# DECODER0_PVDEC_CORE register map
Vendor: Texas Instruments
Peripheral module from a debugger description file (folder J7ES).
Registers are 32-bit, read-write, reset 0x0 unless marked. A register's access mark holds for its fields unless they carry their own. Offsets are as the file gives them; lines under a group give offsets from that group; [hi:lo] are bit positions; {n}, {i} and the like mark numbered series; 'fields as' and 'values as' point back to an identical list; <NAME> marks a mode.

## DECODER0_PVDEC_CORE
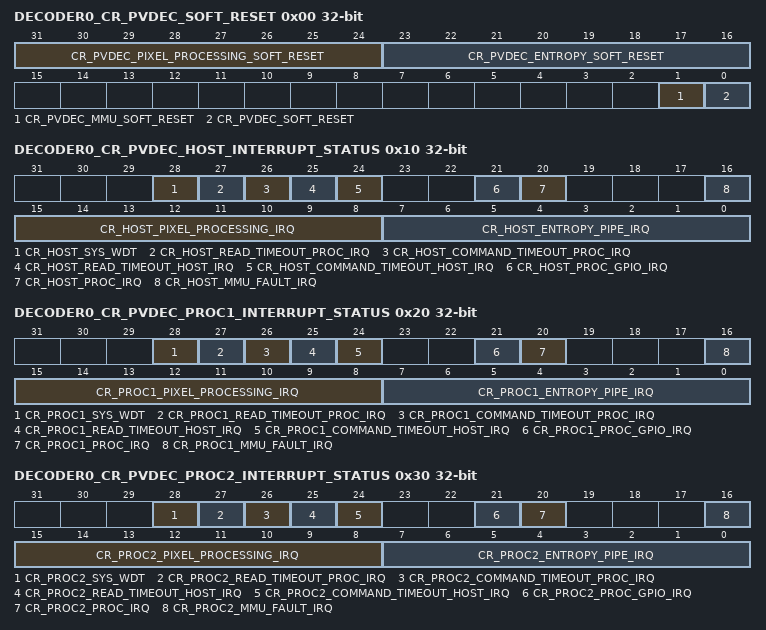
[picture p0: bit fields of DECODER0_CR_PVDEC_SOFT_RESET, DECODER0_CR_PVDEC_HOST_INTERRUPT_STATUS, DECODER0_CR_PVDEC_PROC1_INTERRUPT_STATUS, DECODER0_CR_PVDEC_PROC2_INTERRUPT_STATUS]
0x00 DECODER0_CR_PVDEC_SOFT_RESET
  [31:24] CR_PVDEC_PIXEL_PROCESSING_SOFT_RESET — For each instance of the back-end pixel processing pipe, writing '1' to this bit resets the corresponding pixel processing pipe [where bit 0 resets 'pipe 1', etc.].
  [23:16] CR_PVDEC_ENTROPY_SOFT_RESET — For each instance of the front-end entropy pipe, writing '1' to this bit resets the corresponding front-end entropy pipe [where bit 0 resets 'pipe 1', etc.].
  [1] CR_PVDEC_MMU_SOFT_RESET — Allows the MMU to be reset.
  [0] CR_PVDEC_SOFT_RESET — Allows the core to be reset.
0x10 DECODER0_CR_PVDEC_HOST_INTERRUPT_STATUS
  [28] CR_HOST_SYS_WDT — Timeout condition encountered by system Watch Dog Timer [Pulse generated at event, held by edge detection logic]
  [27] CR_HOST_READ_TIMEOUT_PROC_IRQ — Embedded processor interface timeout of read [command accepted but no data returned] [Pulse generated at event, held by edge detection logic]
  [26] CR_HOST_COMMAND_TIMEOUT_PROC_IRQ — Embedded processor interface timeout of command phase [Pulse generated at event, held by edge detection logic]
  [25] CR_HOST_READ_TIMEOUT_HOST_IRQ — Host interface timeout of read [command accepted but no data returned] [Pulse generated at event, held by edge detection logic]
  [24] CR_HOST_COMMAND_TIMEOUT_HOST_IRQ — Host interface timeout of command phase [Pulse generated at event, held by edge detection logic]
  [21] CR_HOST_PROC_GPIO_IRQ — General purpose interrupt from the embedded processor [Level from register in the embedded processor]
  [20] CR_HOST_PROC_IRQ — Serious interrupt from the embedded processor.
  [16] CR_HOST_MMU_FAULT_IRQ — MMU page fault interrupt, read the
  [15:8] CR_HOST_PIXEL_PROCESSING_IRQ — Pixel processing pipe interrupt, where bit 0 corresponds to 'pixel processing pipe 1', etc.
  [7:0] CR_HOST_ENTROPY_PIPE_IRQ — Entropy pipe interrupt, where bit 0 corresponds to 'entropy pipe 1', etc.
0x14 DECODER0_CR_PVDEC_INTERRUPT_CLEAR
  [31:16] CR_IRQ_CLEAR — The value read from the top half of PVDEC interrupt status registers is based on 'input source' ORed with 'rising edge detection' logic.
0x18 DECODER0_CR_PVDEC_HOST_INTERRUPT_ENABLE
  [31:16] CR_HOST_IRQ_ENABLE — Enables interrupts to the host.
0x20 DECODER0_CR_PVDEC_PROC1_INTERRUPT_STATUS
  [28] CR_PROC1_SYS_WDT — Timeout condition encountered by system Watch Dog Timer [Pulse generated at event, held by edge detection logic]
  [27] CR_PROC1_READ_TIMEOUT_PROC_IRQ — Embedded processor interface timeout of read [command accepted but no data returned] [Pulse generated at event, held by edge detection logic]
  [26] CR_PROC1_COMMAND_TIMEOUT_PROC_IRQ — Embedded processor interface timeout of command phase [Pulse generated at event, held by edge detection logic]
  [25] CR_PROC1_READ_TIMEOUT_HOST_IRQ — Host interface timeout of read [command accepted but no data returned] [Pulse generated at event, held by edge detection logic]
  [24] CR_PROC1_COMMAND_TIMEOUT_HOST_IRQ — Host interface timeout of command phase [Pulse generated at event, held by edge detection logic]
  [21] CR_PROC1_PROC_GPIO_IRQ — General purpose interrupt from the embedded processor [Level from register in the embedded processor]
  [20] CR_PROC1_PROC_IRQ — Serious interrupt from the embedded processor.
  [16] CR_PROC1_MMU_FAULT_IRQ — MMU page fault interrupt, read the
  [15:8] CR_PROC1_PIXEL_PROCESSING_IRQ — Pixel processing pipe interrupt, where bit 0 corresponds to 'pixel processing pipe 1', etc.
  [7:0] CR_PROC1_ENTROPY_PIPE_IRQ — Entropy pipe interrupt, where bit 0 corresponds to 'entropy pipe 1', etc.
0x28 DECODER0_CR_PVDEC_PROC1_INTERRUPT_ENABLE
  [31:16] CR_PROC1_IRQ_ENABLE — Enables interrupts to the embedded processor triggerA.
0x30 DECODER0_CR_PVDEC_PROC2_INTERRUPT_STATUS
  [28] CR_PROC2_SYS_WDT — Timeout condition encountered by system Watch Dog Timer [Pulse generated at event, held by edge detection logic]
  [27] CR_PROC2_READ_TIMEOUT_PROC_IRQ — Embedded processor interface timeout of read [command accepted but no data returned] [Pulse generated at event, held by edge detection logic]
  [26] CR_PROC2_COMMAND_TIMEOUT_PROC_IRQ — Embedded processor interface timeout of command phase [Pulse generated at event, held by edge detection logic]
  [25] CR_PROC2_READ_TIMEOUT_HOST_IRQ — Host interface timeout of read [command accepted but no data returned] [Pulse generated at event, held by edge detection logic]
  [24] CR_PROC2_COMMAND_TIMEOUT_HOST_IRQ — Host interface timeout of command phase [Pulse generated at event, held by edge detection logic]
  [21] CR_PROC2_PROC_GPIO_IRQ — General purpose interrupt from the embedded processor [Level from register in the embedded processor]
  [20] CR_PROC2_PROC_IRQ — Serious interrupt from the embedded processor.
  [16] CR_PROC2_MMU_FAULT_IRQ — MMU page fault interrupt, read the
  [15:8] CR_PROC2_PIXEL_PROCESSING_IRQ — Pixel processing pipe interrupt, where bit 0 corresponds to 'pixel processing pipe 1', etc.
  [7:0] CR_PROC2_ENTROPY_PIPE_IRQ — Entropy core interrupt, where bit 0 corresponds to 'entropy core 1', etc.
0x38 DECODER0_CR_PVDEC_PROC2_INTERRUPT_ENABLE
  [31:16] CR_PROC2_IRQ_ENABLE — Enables interrupts to the embedded processor triggerB.
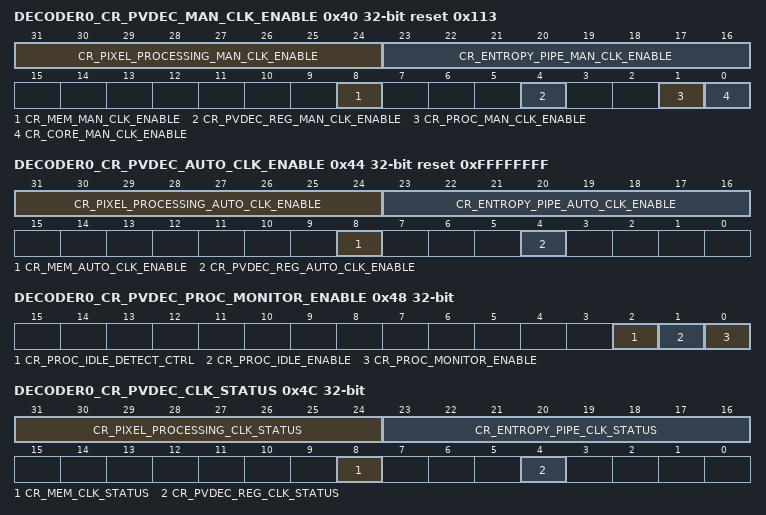
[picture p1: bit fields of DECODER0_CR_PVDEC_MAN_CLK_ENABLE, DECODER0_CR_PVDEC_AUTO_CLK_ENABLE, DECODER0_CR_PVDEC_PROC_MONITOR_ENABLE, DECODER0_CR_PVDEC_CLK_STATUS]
0x40 DECODER0_CR_PVDEC_MAN_CLK_ENABLE reset 0x113
  [31:24] CR_PIXEL_PROCESSING_MAN_CLK_ENABLE — Controls the clock for each instance of the pixel processing pipe [if this bit is set, clock is active and AUTO_CLOCK_ENABLE is ignored].
  [23:16] CR_ENTROPY_PIPE_MAN_CLK_ENABLE — Controls the clock for each instance of the entropy pipe [if this bit is set, clock is active and AUTO_CLOCK_ENABLE is ignored]
  [8] CR_MEM_MAN_CLK_ENABLE — Controls the clock for the PVDEC MMU module [If this bit is set, clock is active and AUTO_CLOCK_ENABLE is ignored]
  [4] CR_PVDEC_REG_MAN_CLK_ENABLE — Controls the clock for the PVDEC core registers [If this bit is set, clock is active and AUTO_CLOCK_ENABLE is ignored]
  [1] CR_PROC_MAN_CLK_ENABLE — Controls the clock for the embedded processor
  [0] CR_CORE_MAN_CLK_ENABLE — Controls the clock for the PVDEC core N.B.
0x44 DECODER0_CR_PVDEC_AUTO_CLK_ENABLE reset 0xFFFFFFFF
  [31:24] CR_PIXEL_PROCESSING_AUTO_CLK_ENABLE — Controls automatic clock gating for each instance of the pixel processing pipe [if MAN_CLK_ENABLE is clear and AUTO_CLOCK_ENABLE is set, clock will stop if pixel processing pipe is idle].
  [23:16] CR_ENTROPY_PIPE_AUTO_CLK_ENABLE — Controls automatic clock gating for each instance of the entropy pipe [if MAN_CLK_ENABLE is clear and AUTO_CLOCK_ENABLE is set, clock will stop if entropy pipe is idle]
  [8] CR_MEM_AUTO_CLK_ENABLE — Controls the clock for the PVDEC MMU module [if MAN_CLK_ENABLE is clear and AUTO_CLOCK_ENABLE is set, clock will stop if MMU is idle]
  [4] CR_PVDEC_REG_AUTO_CLK_ENABLE — Controls the clock for the PVDEC core registers [if MAN_CLK_ENABLE is clear and AUTO_CLOCK_ENABLE is set, clock will stop if PVDEC core register access is idle]
0x48 DECODER0_CR_PVDEC_PROC_MONITOR_ENABLE
  [2] CR_PROC_IDLE_DETECT_CTRL — Sets the method to detect the processor idle status.
  [1] CR_PROC_IDLE_ENABLE — Enables mtx idle signal for clock gating
  [0] CR_PROC_MONITOR_ENABLE — Allows proper setting of idle signals
0x4C DECODER0_CR_PVDEC_CLK_STATUS ro
  [31:24] CR_PIXEL_PROCESSING_CLK_STATUS — Indicates if the clock is enabled to each instance of the pixel processing pipe.
  [23:16] CR_ENTROPY_PIPE_CLK_STATUS — Indicates if the clock is enabled to each instance of the entropy pipe.
  [8] CR_MEM_CLK_STATUS — Indicates if the clock is enabled to MMU
  [4] CR_PVDEC_REG_CLK_STATUS — Indicates if the clock is enabled to PVDEC core registers
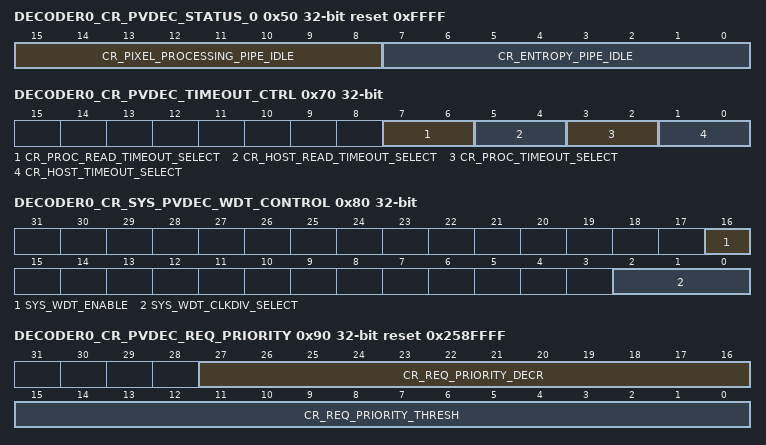
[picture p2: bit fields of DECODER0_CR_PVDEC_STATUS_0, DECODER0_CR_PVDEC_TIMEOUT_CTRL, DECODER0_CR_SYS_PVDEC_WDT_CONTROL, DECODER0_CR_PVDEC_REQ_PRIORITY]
0x50 DECODER0_CR_PVDEC_STATUS_0 ro reset 0xFFFF
  [15:8] CR_PIXEL_PROCESSING_PIPE_IDLE — Indicates the idle signal from pixel_processing_pipe [pixel_idle].
  [7:0] CR_ENTROPY_PIPE_IDLE — Indicates the idle signal from entropy_pipe [entropy_idle].
0x60 DECODER0_CR_PVDEC_HOST_PIPE_SELECT reset 0x1
  [3:0] CR_PVDEC_HOST_PIPE_SELECT — When doing read or write operations from the host to registers of the 'entropy pipe' or 'pixel processing pipe' regions in the first 64kbyte of address space, this register controls which pipeline is accessed.
0x64 DECODER0_CR_PVDEC_PROC_PIPE_SELECT reset 0x1
  [3:0] CR_PVDEC_PROC_PIPE_SELECT — When doing read or write operations from the embedded processor to registers of the 'entropy pipe' or 'pixel processing pipe' regions in the first 64kbyte of address space, this register controls which pipeline is accessed.
0x70 DECODER0_CR_PVDEC_TIMEOUT_CTRL — Controls the maximum timeout value for Host and Embedded processor accesses to the PVDEC core
  [7:6] CR_PROC_READ_TIMEOUT_SELECT — Selects the maximum number of cycles a read can remain outstanding for an embedded processor access before a timeout is flagged to indicate that PVDEC has locked up
  [5:4] CR_HOST_READ_TIMEOUT_SELECT — Selects the maximum number of cycles a read can remain outstanding for a host access before a timeout is flagged to indicate that PVDEC has locked up
  [3:2] CR_PROC_TIMEOUT_SELECT — Selects the maximum number of cycles an outstanding embedded processor access can be stalled before a timeout is flagged to indicate that PVDEC has locked up
  [1:0] CR_HOST_TIMEOUT_SELECT — Selects the maximum number of cycles an outstanding host access can be stalled before a timeout is flagged to indicate that PVDEC has locked up
0x80 DECODER0_CR_SYS_PVDEC_WDT_CONTROL
  [16] SYS_WDT_ENABLE — Watch Dog Timer enable
  [2:0] SYS_WDT_CLKDIV_SELECT — Watch Dog Timer clock select
0x84 DECODER0_CR_SYS_PVDEC_WDTIMER
  [31:0] SYS_WDT_COUNTER — Watch Dog Timer counter value.
0x90 DECODER0_CR_PVDEC_REQ_PRIORITY reset 0x258FFFF — This register controls the generation of a memory priority signal which could be used to dynamically influence the proportion of bandwidth made available to the decoder.
  [27:16] CR_REQ_PRIORITY_DECR — Programmable decrement value for performance counter in range [0,4095]
  [15:0] CR_REQ_PRIORITY_THRESH — Programmable threshold with step size 16 giving range [0,1048560]
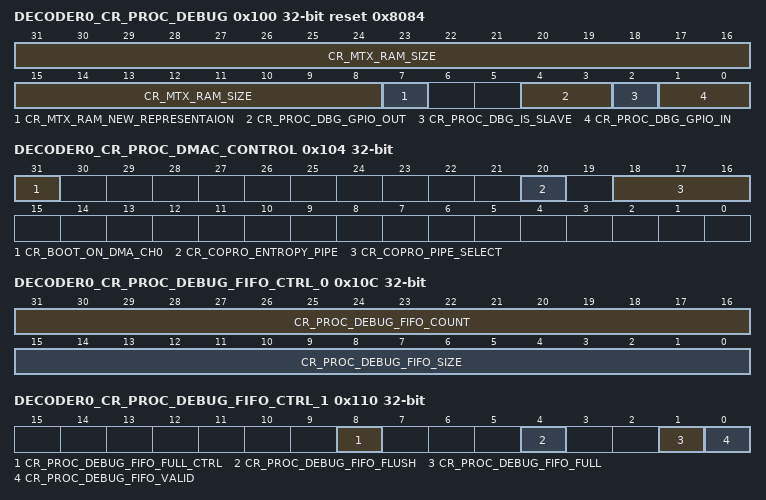
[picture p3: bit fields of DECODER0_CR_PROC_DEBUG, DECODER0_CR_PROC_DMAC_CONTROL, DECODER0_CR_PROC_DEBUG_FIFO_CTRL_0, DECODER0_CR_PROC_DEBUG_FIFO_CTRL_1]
0x100 DECODER0_CR_PROC_DEBUG reset 0x8084
  [31:8] CR_MTX_RAM_SIZE — If MTX_RAM_NEW_REPRESENTAION is 1, {
  [7] CR_MTX_RAM_NEW_REPRESENTAION — Determines whether the MTX RAM size is represented in the new way, as explained in CR_MTX_RAM_SIZE{
  [4:3] CR_PROC_DBG_GPIO_OUT — Data provided by dbg_gpio_out by the embedded processor.
  [2] CR_PROC_DBG_IS_SLAVE — Determines whether the JTAG port of the embedded processor is to be master or slave
  [1:0] CR_PROC_DBG_GPIO_IN — Data for dbg_gpio_in for the embedded processor
0x104 DECODER0_CR_PROC_DMAC_CONTROL
  [31] CR_BOOT_ON_DMA_CH0 — Enables MTX to boot upon DMA Ch0 transfer complete
  [20] CR_COPRO_ENTROPY_PIPE — If the Embedded processor co-processor port is used to access the shift register, if this field is low a Pixel Processing pipe shift register is accessed.
  [18:16] CR_COPRO_PIPE_SELECT — If the Embedded processor co-processor port is used to access the shift register, this register must specify the index of the Pixel Processing pipe or Entropy pipe which contains the shift register to be accessed.
0x108 DECODER0_CR_PROC_DEBUG_FIFO reset 0xFFFFFFFF
  [31:0] CR_PROC_DEBUG_FIFO — Embedded processor may write / read to this register location that is connected to the internal FIFO defined in the Debug FIFO Control register
0x10C DECODER0_CR_PROC_DEBUG_FIFO_CTRL_0 ro
  [31:16] CR_PROC_DEBUG_FIFO_COUNT — Number of valid DWORDS
  [15:0] CR_PROC_DEBUG_FIFO_SIZE — Depth of the Debug FIFO in DWORDS
0x110 DECODER0_CR_PROC_DEBUG_FIFO_CTRL_1
  [8] CR_PROC_DEBUG_FIFO_FULL_CTRL — Controls the write accesses when the Debug FIFO is full
  [4] CR_PROC_DEBUG_FIFO_FLUSH — Flush command for the Debug FIFO [write only]
  [1] CR_PROC_DEBUG_FIFO_FULL — Full flag of the Debug FIFO [read only]
  [0] CR_PROC_DEBUG_FIFO_VALID — Valid flag of the Debug FIFO [read only]
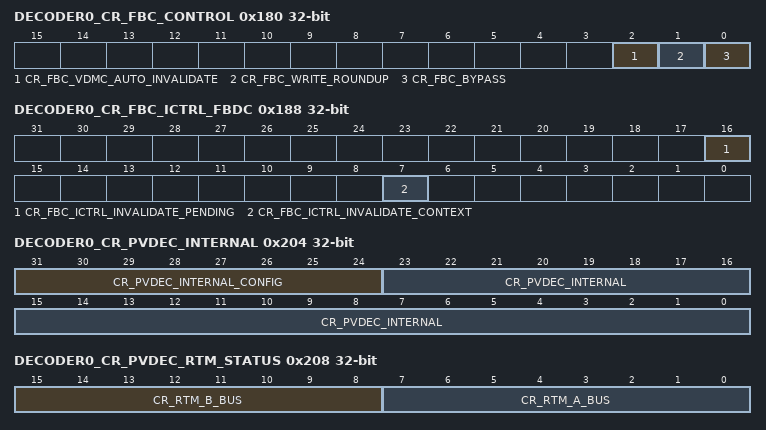
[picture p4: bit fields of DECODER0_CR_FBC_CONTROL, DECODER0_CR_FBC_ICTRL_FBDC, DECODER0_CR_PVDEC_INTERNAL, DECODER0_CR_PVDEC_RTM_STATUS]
0x180 DECODER0_CR_FBC_CONTROL
  [2] CR_FBC_VDMC_AUTO_INVALIDATE — Controls hardware invalidation of FBDC header cache
  [1] CR_FBC_WRITE_ROUNDUP — Controls write bursts for compressed data output by FBC module
  [0] CR_FBC_BYPASS — Even if commnand bus indicates frame buffer compression should be used, this field can be used to bypass the actual compression logic [but the frame store format does change to a tiled 16x4 format]
0x184 DECODER0_CR_FBC_CONTEXT
  [31:28] CR_FBC_PIPE_CONTEXT — In the case of Frame Buffer Compression being used on a multi-pipe HEVC decode, for each pixel pipe in the chain which is not the first, this field should be set to the index of the first pixel pipe in the chain [i.e.
0x188 DECODER0_CR_FBC_ICTRL_FBDC
  [16] CR_FBC_ICTRL_INVALIDATE_PENDING — Writing 1 to this bit triggers invalidation of the FBDC Header Cache, but only entries for which the corresponding context bit is set will be invalidated.
  [7] CR_FBC_ICTRL_INVALIDATE_CONTEXT — Each INVALIDATE_CONTEXT bit corresponds to requests from a specific pipe [bit 0 for pipe 1, bit 1 for pipe 2, etc].
0x204 DECODER0_CR_PVDEC_INTERNAL ro — Revision control register used internally within Imagination to record intermediate versions between release versions
  [31:24] CR_PVDEC_INTERNAL_CONFIG — Revision control register used internally within Imagination to record different hardware configurations for testing purposes
  [23:0] CR_PVDEC_INTERNAL — Revision control register used internally within Imagination to record intermediate versions between release versions
0x208 DECODER0_CR_PVDEC_RTM_STATUS ro
  [15:8] CR_RTM_B_BUS — [Read only field] Read registered version of value output on RTM bus b
  [7:0] CR_RTM_A_BUS — [Read only field] Read registered version of value output on RTM bus a
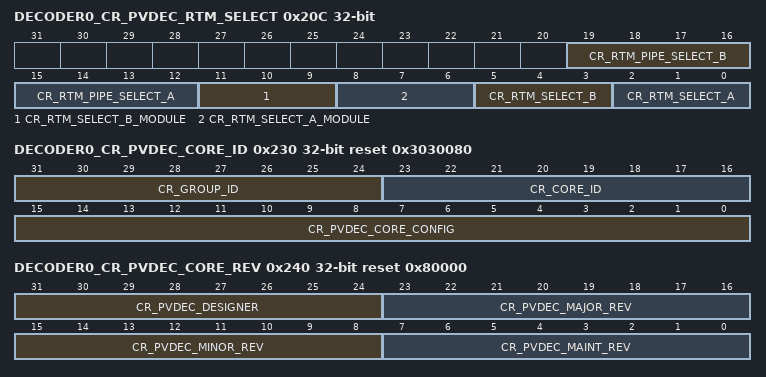
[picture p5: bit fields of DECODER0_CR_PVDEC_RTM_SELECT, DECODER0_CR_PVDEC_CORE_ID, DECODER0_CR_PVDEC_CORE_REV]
0x20C DECODER0_CR_PVDEC_RTM_SELECT
  [19:16] CR_RTM_PIPE_SELECT_B — Each pipe will generate it's own RTM bus, and this field selects the pipe to output on the common RTM bus B
  [15:12] CR_RTM_PIPE_SELECT_A — Each pipe will generate it's own RTM bus, and this field selects the pipe to output on the common RTM bus A
  [11:9] CR_RTM_SELECT_B_MODULE — Selects the module driving the upper 8 bits of the RTM bus
  [8:6] CR_RTM_SELECT_A_MODULE — Selects the module driving the lower 8 bits of the RTM bus
  [5:3] CR_RTM_SELECT_B — Selects the output for the upper 8 bits of the RTM for that module
  [2:0] CR_RTM_SELECT_A — Selects the output for the bottom 8 bits of the RTM for that module
0x230 DECODER0_CR_PVDEC_CORE_ID ro reset 0x3030080
  [31:24] CR_GROUP_ID — This identifies the core as part of an IMG IP family group.
  [23:16] CR_CORE_ID — This identifies the member of the IP group.
  [15:0] CR_PVDEC_CORE_CONFIG — IMG Core Configuration:-
0x240 DECODER0_CR_PVDEC_CORE_REV ro reset 0x80000
  [31:24] CR_PVDEC_DESIGNER — Company ID [Allocated by IMG]
  [23:16] CR_PVDEC_MAJOR_REV — IMG Family Major Revision.
  [15:8] CR_PVDEC_MINOR_REV — IMG Core Minor Revision.
  [7:0] CR_PVDEC_MAINT_REV — IMG Maintenance Revision.
0x270 DECODER0_CR_PVDEC_RSVD0
  [31:0] CR_RSVD0 — Reserved
